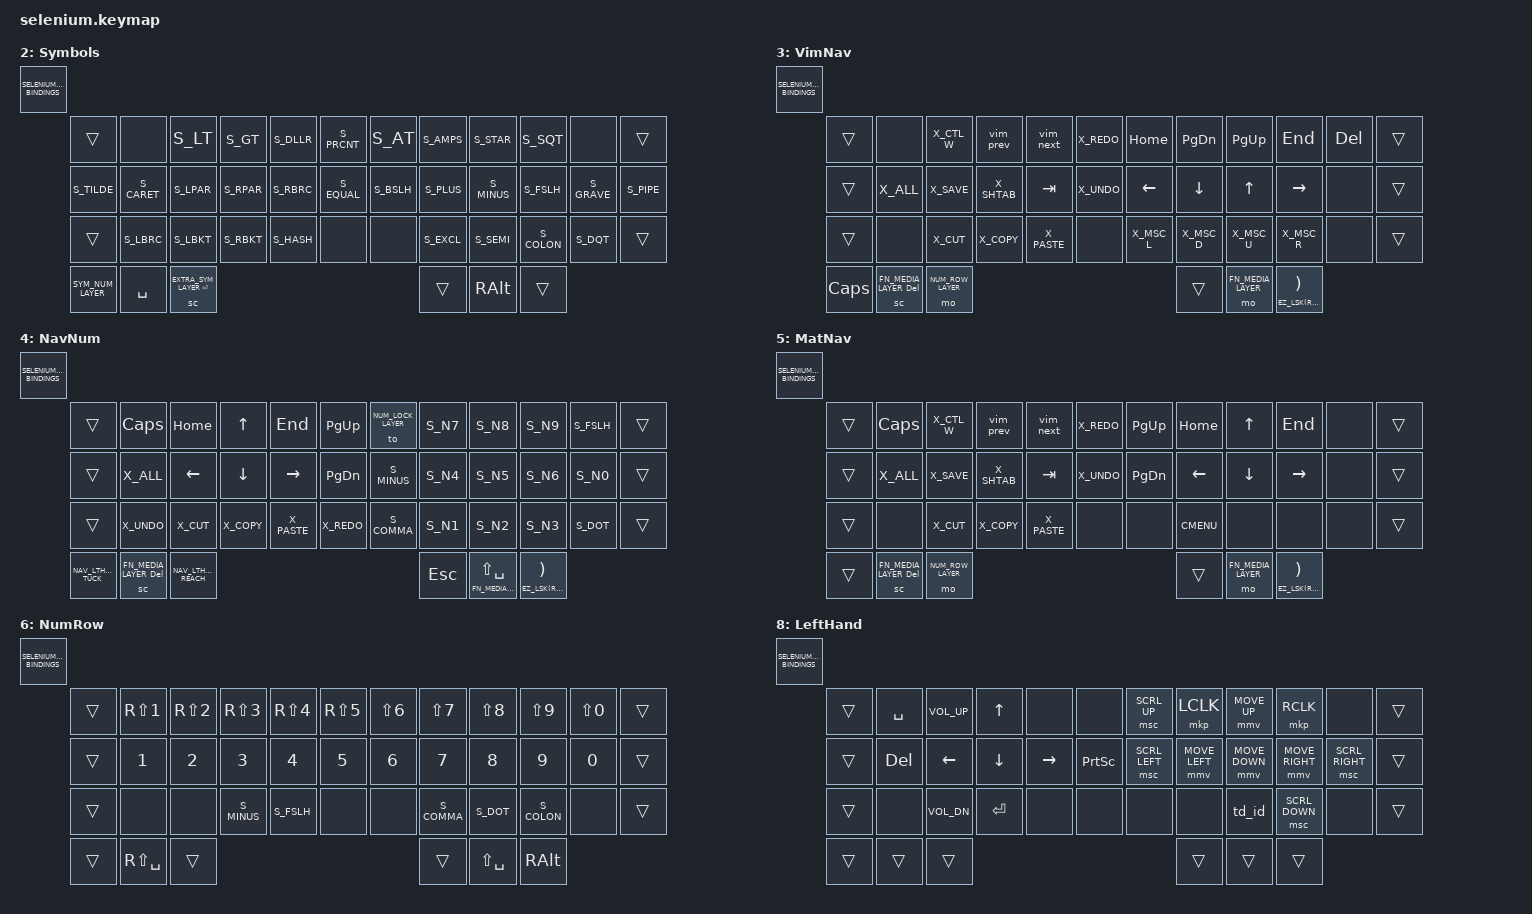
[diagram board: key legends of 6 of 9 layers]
// Selenium keymap:
// https://github.com/OneDeadKey/selenium

#include <dt-bindings/zmk/bt.h> // bluetooth behaviors (see fn/media layer)
#include <dt-bindings/zmk/pointing.h> // Necessary for mouse stuff

#ifndef CI_IGNORE_USER_SETTINGS
  #include "settings.h"   // user settings
#endif

#include "defaults.h"     // default options and safeguards
#include "aliases.h"      // defines symbols and actions
#include "bindings.h"     // default SELENIUM_KEYMAP_BINDINGS macro
#include "mappings.dtsi"  // key mapping helpers and macros
#include "hold_taps.dtsi" // defines thumb keys and homerow mods


/**
 * All keyboard layers are defined by blocks on a 42-key basis, as follows:
 *
 *   <SELENIUM_KEYMAP_BINDINGS(
 *     Tab   , QWERT , YUIOP , BkSpc ,
 *     Esc   , ASDFG , HJKL: , Enter ,
 *     Shift , ZXCVB , NM<>? , Shift ,
 *      LT1, LT2, LT3, RT3, RT2, RT1
 *   )>
 *
 * Where LTx/RTx are the left/right thumb keys.
 * Beware: missing or misplacing a comma in the definitions below would break the keymap.
 */

/ {

  // Define a couple of macros for a tap dance for n o m s et autres
  macros {
    macro_p: macro_p {
        compatible = "zmk,behavior-macro";
        #binding-cells = <0>;
        wait-ms = <30>;
        tap-ms = <30>;
        bindings = <&kp LS(U) &kp A &kp K &kp M &kp L &kp H &kp I &kp D>;
      };

      macro_n: macro_n {
        compatible = "zmk,behavior-macro";
        #binding-cells = <0>;
        wait-ms = <30>;
        tap-ms = <30>;
        bindings = <&kp LS(U) &kp E &kp SEMICOLON &kp S &kp S &kp D &kp K>;
      };

      macro_pn: macro_pn {
        compatible = "zmk,behavior-macro";
        #binding-cells = <0>;
        wait-ms = <30>;
        tap-ms = <30>;
        bindings = <&macro_p>, <&kp SPACE>, <&macro_n>;
      };

      macro_ml: macro_ml {
        compatible = "zmk,behavior-macro";
        #binding-cells = <0>;
        wait-ms = <50>;
        tap-ms = <50>;
        bindings 
          = <&kp U &kp A &kp K &kp M &kp L &kp H &kp I &kp D>
          , <&kp N>
          , <&kp U &kp E &kp SEMICOLON &kp S &kp S &kp D &kp> 
          , <K S_AT>
          , <&kp D &kp R &kp L &kp W &kp D &kp F &kp K &kp J &kp D>
          , <&kp N> 
          , <&kp U &kp S &kp G>
          , <&kp N> 
          , <&kp E &kp J &kp COMMA>;
      };  
    };


  keymap {
    compatible = "zmk,keymap";

    // 0. Base layer -- keep the QWERTY key codes to use your OS keyboard layout
    //               -- the Space Cadet layer-tap on the right can be replaced by an AltGr/Enter mod-tap
    //               -- adjust the homerow mods with the #define statements above
    base_layer: base_layer {
      display-name = "Base";
      bindings = <SELENIUM_KEYMAP_BINDINGS(
        &none                    , &none  &kp W  &kp E  &kp R  &kp T  ,  &kp N  &kp U  &kp I      &apos    &none    , &none                     ,
        &EZ_SL(LEFT_MOUSE_LAYER) , HRM_A  HRM_S  HRM_D  HRM_F  &kp G  ,  &kp H  HRM_J  HRM_K      HRM_L    HRM_SEMI , &lt FN_MEDIA_LAYER SPACE  ,
        &none                    , &kp Q  &kp X  &kp C  &kp V  &none  ,  &none  &kp M  &kp COMMA  &kp DOT  &kp P    , &tp_num_lock              ,
                            LTHUMB_TUCK , LTHUMB_HOME , LTHUMB_REACH  ,  RTHUMB_REACH , RTHUMB_HOME , RTHUMB_TUCK
      )>;
    };
    
    // 1. NumLock layer -- a NavNum layer that stays on until deactivated without holding any key
    num_lock_layer: num_lock_layer {
      display-name = "NumLock";
      bindings = <SELENIUM_KEYMAP_BINDINGS(
        &trans  ,  &kp ESC  &kp HOME &kp UP   &kp END   &kp PG_UP   ,   &to BASE_LAYER S_N7  S_N8  S_N9  S_FSLH  ,  &trans ,
        &trans  ,  S_EQUAL  &kp LEFT &kp DOWN &kp RIGHT &kp PG_DN   ,   S_MINUS        S_N4  S_N5  S_N6  S_N0    ,  &trans ,
        &trans  ,  S_MONEY  S_COLON  S_STAR   S_PLUS    S_PRCNT     ,   S_COMMA        S_N1  S_N2  S_N3  S_DOT   ,  &trans ,
                 &trans , &sc NAV_NUM_LAYER BACKSPACE , &kp (TAB)   ,   &trans , &lt NAV_NUM_LAYER LS(SPACE) , &EZ_SL(SYMBOLS_LAYER)
      )>;
    };

    // 2. Symbols layer -- with Ergol, basically just an AltGr layer with custom thumb keys
    //                  -- can be redefined for non-AltGr layouts such as QWERTY-ANSI
    //                  -- since I use the underscore mostly from the symbol lyer, I inverted the hashtag and the underscore
    //      -- Add access to a sticky layer that can contain the missing symbols on left reach thumb
    // (it's not really required for this config (with keys on outer columns) but I kept it in case.
    // It does ENTER on tap and access the new layer on hold.
    //      -- Get read of the ?, which I can access through the base layer
    //      -- Remplace the underscore by le hashtag (I only use the 1D)
    //      -- Move the tilde and the pipe in outer columns
    symbols_layer: symbols_layer {
      display-name = "Symbols";
      bindings = <SELENIUM_KEYMAP_BINDINGS(
        &trans  ,  &none    S_LT    S_GT    S_DLLR  S_PRCNT  ,   S_AT    S_AMPS  S_STAR  S_SQT   &none   ,  &trans ,
        S_TILDE ,  S_CARET  S_LPAR  S_RPAR  S_RBRC  S_EQUAL  ,   S_BSLH  S_PLUS  S_MINUS S_FSLH  S_GRAVE ,  S_PIPE ,
        &trans  ,  S_LBRC   S_LBKT  S_RBKT  S_HASH  &none    ,   &none   S_EXCL  S_SEMI  S_COLON S_DQT   ,  &trans ,
        SYM_NUM_LAYER , &kp SPACE ,  &sc EXTRA_SYM_LAYER ENTER   ,   &trans , &kp RALT ,  &trans
      )>;
    };

    // 3. VimNav layer -- HJKL arrow cluster on the right hand
    //                 -- best used along with the NumRow layer
    //                 -- keyboard shortcuts on the left hand are adjusted to the OS layout (Ergol here)
    //                 -- X_MSC_L and Co on bottom right row are scrolling actions, vim-like
    vim_nav_layer: vim_nav_layer {
      display-name = "VimNav";
      bindings = <SELENIUM_KEYMAP_BINDINGS(
        &trans  ,  &none    X_CTL_W  &vim_prev &vim_next X_REDO    ,   &kp HOME &kp PG_DN &kp PG_UP &kp END   &kp DEL ,  &trans ,
        &trans  ,  X_ALL    X_SAVE   X_SHTAB   &kp TAB   X_UNDO    ,   &kp LEFT &kp DOWN  &kp UP    &kp RIGHT &none   ,  &trans ,
        &trans  ,  &none    X_CUT    X_COPY    X_PASTE   &none     ,   X_MSC_L  X_MSC_D   X_MSC_U   X_MSC_R   &none   ,  &trans ,
            &kp CAPS , &sc FN_MEDIA_LAYER DEL , &mo NUM_ROW_LAYER  ,   &trans ,  &mo FN_MEDIA_LAYER , &EZ_LSK(RALT)
      )>;
    };

    // 4. NavNum layer -- inverted T arrow cluster on the left hand, numpad on the right hand
    //                 -- can be the only extra layer you need if you're not too picky with number+symbols n-grams
    //                 -- keyboard shortcuts on the left hand are adjusted to the OS layout (Ergol here)
    //                 -- I replaced the ESC by a CAPS on the top left
    nav_num_layer: nav_num_layer {
      display-name = "NavNum";
      bindings = <SELENIUM_KEYMAP_BINDINGS(
        &trans  ,  &kp CAPS &kp HOME &kp UP   &kp END   &kp PG_UP   ,   &to NUM_LOCK_LAYER S_N7  S_N8  S_N9  S_FSLH  ,  &trans ,
        &trans  ,  X_ALL    &kp LEFT &kp DOWN &kp RIGHT &kp PG_DN   ,   S_MINUS            S_N4  S_N5  S_N6  S_N0    ,  &trans ,
        &trans  ,  X_UNDO   X_CUT    X_COPY   X_PASTE   X_REDO      ,   S_COMMA            S_N1  S_N2  S_N3  S_DOT   ,  &trans ,
      NAV_LTHUMB_TUCK , &sc FN_MEDIA_LAYER DEL , NAV_LTHUMB_REACH   ,   &kp ESCAPE , &lt FN_MEDIA_LAYER LS(SPACE) , &EZ_LSK(RALT)
      )>;
    };

    // 5. MatNav layer  -- a mix between the vimnav and numnav layer
    //                  -- keeps the powerful left block of VimNav
    //                  -- has a cluster of arrows more similar to NavNum, for non vim users
    //                  -- to be used with the NumRow, as an alternative to VimNav
    matnav_layer: matnav_layer {
      display-name = "MatNav";
      bindings = <SELENIUM_KEYMAP_BINDINGS(
        &trans , &kp CAPS X_CTL_W  &vim_prev &vim_next  X_REDO  ,   &kp PG_UP  &kp HOME     &kp UP    &kp END    &none ,  &trans ,
        &trans , X_ALL    X_SAVE   X_SHTAB   &kp TAB    X_UNDO  ,   &kp PG_DN  &kp LEFT     &kp DOWN  &kp RIGHT  &none ,  &trans ,
        &trans , &none    X_CUT    X_COPY    X_PASTE    &none   ,   &none      &kp K_CMENU  &none     &none      &none ,  &trans ,
          &trans , &sc FN_MEDIA_LAYER DEL , &mo NUM_ROW_LAYER   ,   &trans , &mo FN_MEDIA_LAYER , &EZ_LSK(RALT)
      )>;
    };



    // 5. NumRow layer -- bring the numbers to the homerow, keep shift+numbers for shortcuts and symbols
    //                 -- space becomes shift+space, which is a no-break space with some OS layouts (e.g. Ergol)
    //                 -- best used along with the VimNav layer
    num_row_layer: num_row_layer {
      display-name = "NumRow";
      bindings = <SELENIUM_KEYMAP_BINDINGS(
        &trans  ,  &kp RS(N1) &kp RS(N2) &kp RS(N3) &kp RS(N4) &kp RS(N5)  ,  &kp LS(N6) &kp LS(N7) &kp LS(N8) &kp LS(N9) &kp LS(N0) , &trans ,
        &trans  ,  &kp N1     &kp N2     &kp N3     &kp N4     &kp N5      ,  &kp N6     &kp N7     &kp N8     &kp N9     &kp N0     , &trans ,
        &trans  ,  &none      &none      S_MINUS    S_FSLH     &none       ,  &none      S_COMMA    S_DOT      S_COLON    &none      , &trans ,
                                      &trans , &kp RS(SPACE) , &trans      ,  &trans , &kp LS(SPACE) , &kp RALT
      )>;
    };

    // 7. FnMedia layer -- F1..12 pad on the left hand, HRM on the right hand
    //                  -- reset and bootloader reset on difficult thumb keys
    //                  -- could be completed with other rare keys
    //                  
    //                  -- I got rid of the scrolllock which is useless to me
    //                  -- I also moved the Fn keys so that I have five per rows
    fn_media_layer: fn_media_layer {
      display-name = "FnMedia";
      bindings = <SELENIUM_KEYMAP_BINDINGS(
        &trans  ,  &kp F1  &kp F2  &kp F3   &kp F4  &kp F5   ,  &none   &kp C_NEXT  &kp C_VOL_UP  &kp C_BRI_UP   &to NUM_LOCK_LAYER  ,  &trans ,
        &trans  ,  &kp F6  &kp F7  &kp F8   &kp F9  &kp F10  ,  &none   H_J C_PP    H_K C_MUTE    H_L C_AL_LOCK  H_SEMI PSCRN        ,  &trans ,
        &trans  ,  &none   &kp F11 &kp F12  &none   &none    ,  &none   &kp C_PREV  &kp C_VOL_DN  &kp C_BRI_DN   &none               ,  &trans ,
                            &trans , &bootloader , &trans    ,  &trans , &sys_reset , &studio_unlock
      )>;
    };

    // 8. Left-hand layer   -- some useful keys for when using the mouse (not a miror layer)
    //                      -- try out alternative shape for volume
    //                      -- test some mouse actions as well. Might go to other layer… or not if I like it.
    left_hand_layer: left_hand_layer {
      display-name = "LeftHand";
        bindings = <SELENIUM_KEYMAP_BINDINGS(
          &trans , &kp SPACE  &kp C_VOL_UP   &kp UP     &none      &none      ,   &msc SCRL_UP    &mkp LCLK       &mmv MOVE_UP    &mkp RCLK        &none           , &trans ,
          &trans , &kp DEL    &kp LEFT       &kp DOWN   &kp RIGHT  &kp PSCRN  ,   &msc SCRL_LEFT  &mmv MOVE_LEFT  &mmv MOVE_DOWN  &mmv MOVE_RIGHT  &msc SCRL_RIGHT , &trans ,
          &trans , &none      &kp C_VOL_DN   &kp ENTER  &none      &none      ,   &none           &none           &td_id          &msc SCRL_DOWN   &none           , &trans ,
                                            &trans , &trans , &trans          ,   &trans , &trans , &trans
        )>;
      };

  };
};


// Emulated layouts (experimental!)
#ifdef KB_EMULATION_DVORAK
  #include "emulations/dvorak.dtsi"
#elif defined KB_EMULATION_ERGOL
  #include "emulations/ergol.dtsi"
#elif defined KB_EMULATION_QWERTY_LAFAYETTE
  #include "emulations/qwerty_lafayette.dtsi"
#endif

// Some layouts require extra layers to fit on the Quacken.
#ifdef KB_LAYOUT_AZERTY
  #include "extra_layers/azerty.dtsi"
#elif defined KB_LAYOUT_BEPO
  #include "extra_layers/bepo.dtsi"
#elif defined KB_LAYOUT_ERGOL && defined HUMMINGBIRD
  #include "extra_layers/ergol_hummingbird.dtsi"
#elif defined KB_LAYOUT_ERGOL && defined MARTINET
  #include "extra_layers/ergol_martinet.dtsi"
#endif
